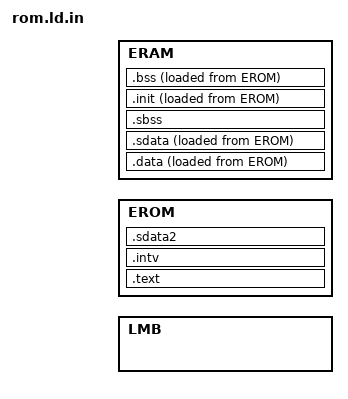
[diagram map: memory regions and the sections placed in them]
/* Simple development memory map for Xilinx Microblaze target.
   Assume that only the interrupt vectors and the small local data
   area go in LMB RAM, and that some mythical bootloader will 
   put the kernel into EXT_RAM 
*/

/* Get all the autoconfigure addresses etc */
#include <linux/config.h>
#include <asm/clinkage.h>

MEMORY {
	LMB  : ORIGIN = CONFIG_XILINX_LMB_START, 
	       LENGTH = CONFIG_XILINX_LMB_SIZE
	EROM  : ORIGIN = CONFIG_XILINX_EROM_START,
                LENGTH = CONFIG_XILINX_EROM_SIZE
	ERAM  : ORIGIN = CONFIG_XILINX_ERAM_START,
                LENGTH = CONFIG_XILINX_ERAM_SIZE
}

SECTIONS {
	.text : {
		_stext = . ;
        	*(.text)
			*(.text.exit)
			*(.text.lock)
			*(.exitcall.exit)
			*(.rodata)
		*(.modinfo)
		. = ALIGN (0x4) ;
			*(.kstrtab)
		. = ALIGN (16) ;	/* Exception table.  */
		__start___ex_table = . ;
			*(_ex_table)
		__stop___ex_table = . ;

		__start___ksymtab = . ; /* All kernel symbols */
		*(__ksymtab)
		__stop___ksymtab = . ;

                __start___kallsyms = .; /* All kernel symbols           */
                        *(__kallsyms)
                __stop___kallsyms = .;


		. = ALIGN (4) ;
		_etext = . ;
	} > EROM

	/* Copies of interrupt vector space. They get copied from here into the 
  	   proper location by mach_early_setup() */ 
	.intv : {
		_intv_load_start = . ;
	        	*(.intv.reset)	/* Reset vector */
			*(.intv.common) /* Vectors common to all microblaze proc. */
			*(.intv.mach)   /* Machine-specific int. vectors.  */
		_intv_load_end = . ;
	} > EROM


	/* sdata2 section can go anywhere, but must be word aligned
	   and SDA2_BASE must point to the middle of it */
	.sdata2 : {
		_ssrw = .;
		. = ALIGN(0x8);
		*(.sdata2)
	. = ALIGN(8);
	_essrw = .;
	_ssrw_size = _essrw - _ssrw;
	_KERNEL_SDA2_BASE_ = _ssrw + (_ssrw_size / 2);
	} > EROM


	.data : {
		/* "untouchable" memory space starts here */
	        _kram_start = . ;

		. = ALIGN (0x4);
		__data_vma_start = .;
		_sdata = . ;
		__data_start = . ;
        	*(.data)
			*(.data.exit)
		. = ALIGN (16) ;
		*(.data.cacheline_aligned)
		. = ALIGN (0x2000) ;
        	*(.data.init_task)
		. = ALIGN (0x2000) ;
		_edata = . ;
	
		/* Reserve some low RAM for r0 based memory references */
		. = ALIGN(4) ;
		C_SYMBOL_NAME(r0_ram) = . ;
		. = . + 32 ;	/* 32 bytes should be enough */
		__data_vma_end = .;
	} > ERAM AT > EROM
	__data_lma = LOADADDR(.data);

	/* Under the microblaze ABI, .sdata and .sbss must be contiguous */
	. = ALIGN(8);
	.sdata : {
		__sdata_vma_start = .;
		_ssro = .;
		*(.sdata)
		__sdata_vma_end = .;
	} > ERAM AT > EROM
	__sdata_lma = LOADADDR(.sdata);

	. = ALIGN(4);
	.sbss : {
		_ssbss = . ;
		_sbss_start = .;
		*(.sbss)
		_ssbss_end = .;
		_esbss = . ;

	. = ALIGN(8);
	_essro = .;
	_ssro_size = _essro - _ssro;
	_KERNEL_SDA_BASE_ = _ssro + (_ssro_size / 2);
	
 	} > ERAM
 
	/* Place init and bootmap sections last to reduce fragmentation 
	   when they are freed */
 	.init ALIGN (4096) : {
		__init_vma_start = .;
 		_init_start = . ;
		__init_begin = . ;
 			*(.text.init)
 			*(.data.init)
 		. = ALIGN (16) ;
 		__setup_start = . ;
 			*(.setup.init)
 		__setup_end = . ;
 		__initcall_start = . ;
 			*(.initcall.init)
 		. = ALIGN (4) ;
 		__initcall_end = . ;
		. = ALIGN(4096);
		__init_end = . ;
 		_init_end = . ;
		__init_vma_end = .;
 		/* Untouchable kernel ram ends here */
 		_kram_end = . ;
 	} > ERAM AT > EROM
	__init_lma = LOADADDR(.init);

	/* .bss must go last, to be compatible with the way the romfs is handled */
	.bss ALIGN (0x4) : {
		_sbss = . ;
		__bss_start = .;
			*(.bss*)
			*(COMMON)
		. = ALIGN (4) ;
		__bss_stop = . ;
		_ebss = . ;
		_end = . ;
 	} > ERAM AT > EROM
	__bss_lma = LOADADDR(.bss);
	__ebss_lma = __bss_lma + _ebss - _sbss;
 
}

